AUTOSAR XML (schema 4-2-2)
package /Components
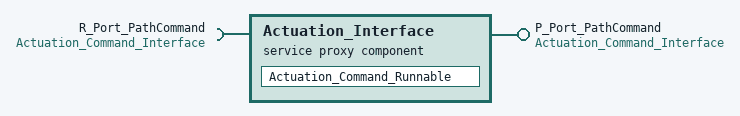
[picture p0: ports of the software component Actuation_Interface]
  service proxy sw component type Actuation_Interface
    provide port P_Port_PathCommand: provided-interface=Actuation_Command_Interface
    require port R_Port_PathCommand: required-interface=Actuation_Command_Interface
    behavior Actuation_Interface_BHV
      data write completed event ActuationCommandWritten: start-on-event=Actuation_Command_Runnable, event-source=R_Port_PathCommand
      runnable Actuation_Command_Runnable: symbol=Actuation_Command_Symbol
        data-receive-point-by-arguments:
          access PathCommand_Input: accessed-variable={autosar-variable-in-impl-datatype={port-prototype=R_Port_PathCommand, target-data-prototype=ActuationCommand}, autosar-variable=R_Port_PathCommand.CameraImageData}
        data-send-points:
          access ActuatorCommand_Output: accessed-variable={autosar-variable-in-impl-datatype={port-prototype=P_Port_ActuatorCommand, target-data-prototype=ActuationCommand}, autosar-variable=P_Port_ActuatorCommand.CameraImageData}
